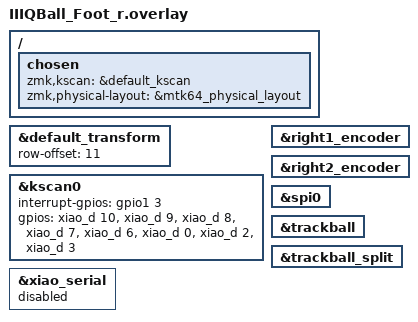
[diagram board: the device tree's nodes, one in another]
#include "IIIQBall_Foot.dtsi"
#include "IIIQBall_Foot_trackball.dtsi"

/ {
    chosen {
        zmk,kscan = &default_kscan;
        zmk,physical-layout = &mtk64_physical_layout;
    };
};

&default_transform {
    row-offset = <11>;
};

&kscan0 {
    interrupt-gpios = <&gpio1 3 (GPIO_ACTIVE_HIGH | GPIO_PULL_DOWN)>;
    gpios = 
        <&xiao_d 10 GPIO_ACTIVE_HIGH>,
        <&xiao_d 9  GPIO_ACTIVE_HIGH>,
        <&xiao_d 8  GPIO_ACTIVE_HIGH>,
        <&xiao_d 7  GPIO_ACTIVE_HIGH>,
        <&xiao_d 6  GPIO_ACTIVE_HIGH>,
        <&xiao_d 0  GPIO_ACTIVE_HIGH>,
        <&xiao_d 2  GPIO_ACTIVE_HIGH>,
        <&xiao_d 3  GPIO_ACTIVE_HIGH>;
};

&right1_encoder { status = "okay"; };
&right2_encoder { status = "okay"; };

&spi0 {
    status = "okay";
};

&trackball { 
    status = "okay";
};

&trackball_split { 
    status = "okay";
};

&xiao_serial { status = "disabled"; };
